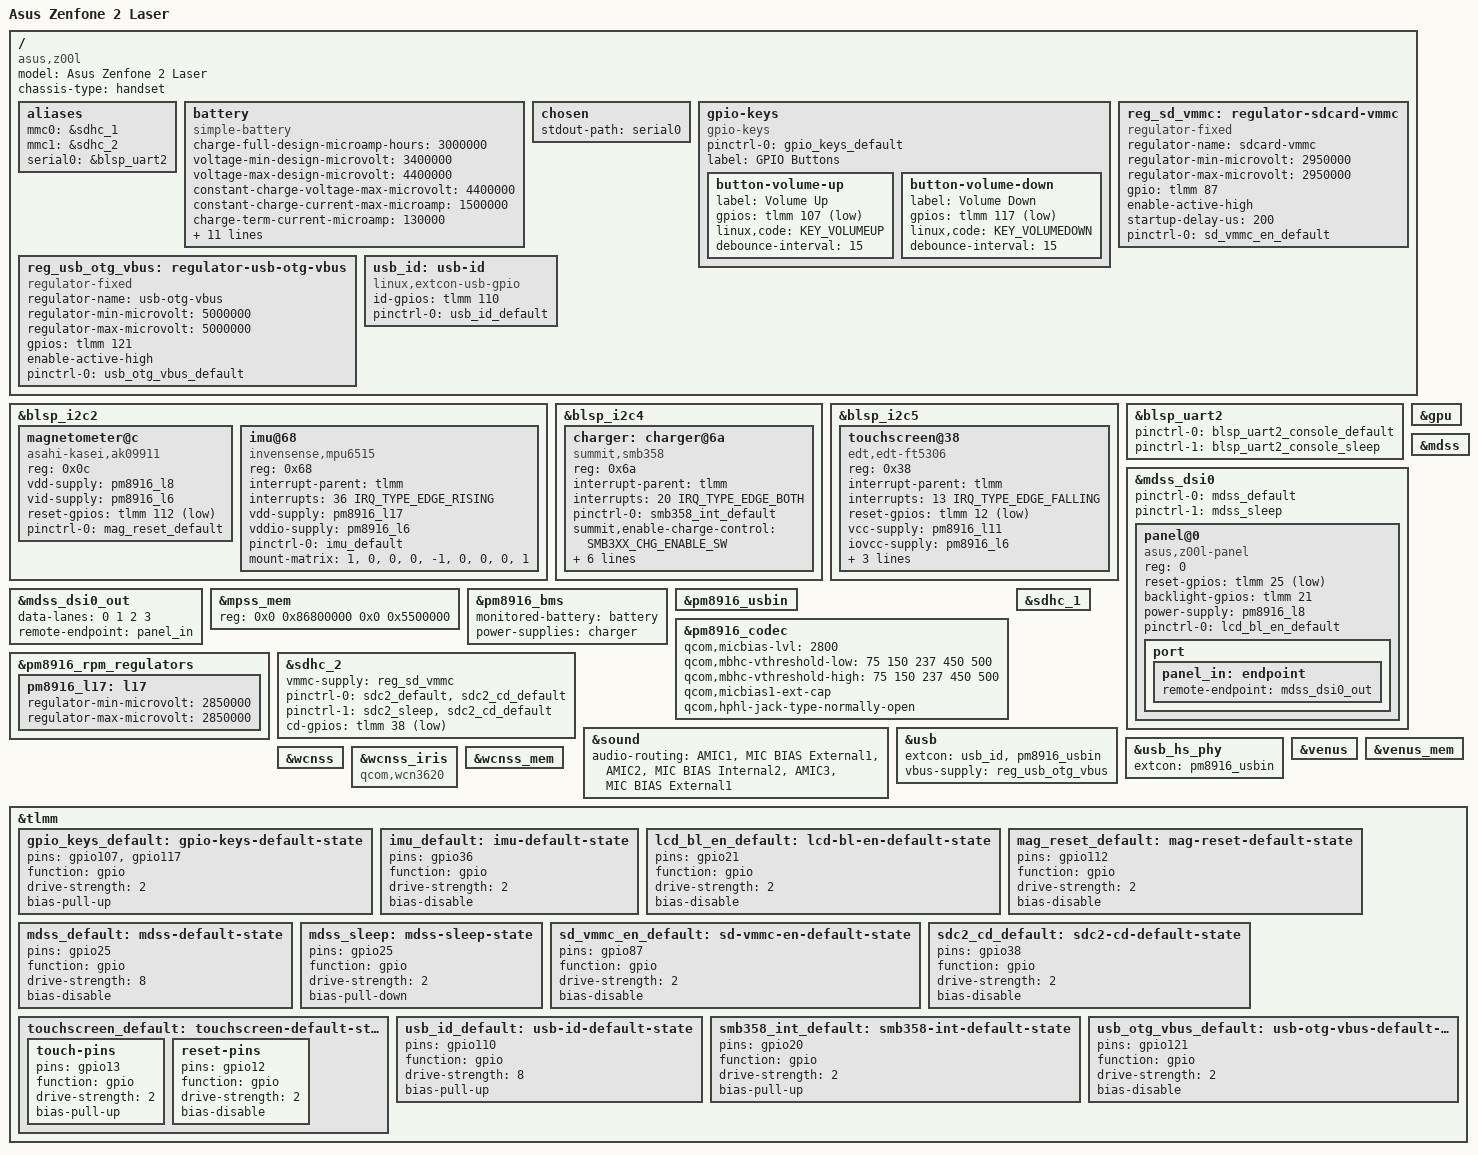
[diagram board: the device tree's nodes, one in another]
// SPDX-License-Identifier: GPL-2.0-only

/dts-v1/;

#include "msm8916-pm8916.dtsi"
#include "msm8916-modem-qdsp6.dtsi"

#include <dt-bindings/gpio/gpio.h>
#include <dt-bindings/input/input.h>
#include <dt-bindings/interrupt-controller/irq.h>
#include <dt-bindings/power/summit,smb347-charger.h>

/ {
	model = "Asus Zenfone 2 Laser";
	compatible = "asus,z00l", "qcom,msm8916";
	chassis-type = "handset";

	aliases {
		mmc0 = &sdhc_1; /* eMMC */
		mmc1 = &sdhc_2; /* SD card */
		serial0 = &blsp_uart2;
	};

	battery: battery {
		compatible = "simple-battery";

		charge-full-design-microamp-hours = <3000000>;
		voltage-min-design-microvolt = <3400000>;
		voltage-max-design-microvolt = <4400000>;
		constant-charge-voltage-max-microvolt = <4400000>;

		constant-charge-current-max-microamp = <1500000>;
		charge-term-current-microamp = <130000>;

		ocv-capacity-celsius = <25>;
		ocv-capacity-table-0 = <4372000 100>, <4306000 95>, <4247000 90>,
				       <4190000 85>,  <4134000 80>, <4081000 75>,
				       <4030000 70>,  <3984000 65>, <3930000 60>,
				       <3884000 55>,  <3850000 50>, <3826000 45>,
				       <3804000 40>,  <3786000 35>, <3770000 30>,
				       <3753000 25>,  <3734000 20>, <3712000 16>,
				       <3693000 13>,  <3686000 11>, <3684000 10>,
				       <3682000 9>,   <3680000 8>,  <3676000 7>,
				       <3668000 6>,   <3643000 5>,  <3600000 4>,
				       <3542000 3>,   <3462000 2>,  <3340000 1>,
				       <3000000 0>;
	};

	chosen {
		stdout-path = "serial0";
	};

	gpio-keys {
		compatible = "gpio-keys";

		pinctrl-names = "default";
		pinctrl-0 = <&gpio_keys_default>;

		label = "GPIO Buttons";

		button-volume-up {
			label = "Volume Up";
			gpios = <&tlmm 107 GPIO_ACTIVE_LOW>;
			linux,code = <KEY_VOLUMEUP>;
			debounce-interval = <15>;
		};

		button-volume-down {
			label = "Volume Down";
			gpios = <&tlmm 117 GPIO_ACTIVE_LOW>;
			linux,code = <KEY_VOLUMEDOWN>;
			debounce-interval = <15>;
		};
	};

	reg_sd_vmmc: regulator-sdcard-vmmc {
		compatible = "regulator-fixed";
		regulator-name = "sdcard-vmmc";
		regulator-min-microvolt = <2950000>;
		regulator-max-microvolt = <2950000>;

		gpio = <&tlmm 87 GPIO_ACTIVE_HIGH>;
		enable-active-high;

		startup-delay-us = <200>;

		pinctrl-names = "default";
		pinctrl-0 = <&sd_vmmc_en_default>;
	};

	reg_usb_otg_vbus: regulator-usb-otg-vbus {
		compatible = "regulator-fixed";
		regulator-name = "usb-otg-vbus";
		regulator-min-microvolt = <5000000>;
		regulator-max-microvolt = <5000000>;

		gpios = <&tlmm 121 GPIO_ACTIVE_HIGH>;
		enable-active-high;

		pinctrl-names = "default";
		pinctrl-0 = <&usb_otg_vbus_default>;
	};

	usb_id: usb-id {
		compatible = "linux,extcon-usb-gpio";
		id-gpios = <&tlmm 110 GPIO_ACTIVE_HIGH>;
		pinctrl-names = "default";
		pinctrl-0 = <&usb_id_default>;
	};
};

&blsp_i2c2 {
	status = "okay";

	magnetometer@c {
		compatible = "asahi-kasei,ak09911";
		reg = <0x0c>;

		vdd-supply = <&pm8916_l8>;
		vid-supply = <&pm8916_l6>;

		reset-gpios = <&tlmm 112 GPIO_ACTIVE_LOW>;

		pinctrl-names = "default";
		pinctrl-0 = <&mag_reset_default>;
	};

	imu@68 {
		compatible = "invensense,mpu6515";
		reg = <0x68>;

		interrupt-parent = <&tlmm>;
		interrupts = <36 IRQ_TYPE_EDGE_RISING>;

		vdd-supply = <&pm8916_l17>;
		vddio-supply = <&pm8916_l6>;

		pinctrl-names = "default";
		pinctrl-0 = <&imu_default>;

		mount-matrix = "1",  "0", "0",
			       "0", "-1", "0",
			       "0",  "0", "1";
	};
};

&blsp_i2c4 {
	status = "okay";

	charger: charger@6a {
		compatible = "summit,smb358";
		reg = <0x6a>;

		interrupt-parent = <&tlmm>;
		interrupts = <20 IRQ_TYPE_EDGE_BOTH>;

		pinctrl-names = "default";
		pinctrl-0 = <&smb358_int_default>;

		summit,enable-charge-control = <SMB3XX_CHG_ENABLE_SW>;
		summit,inok-polarity = <SMB3XX_SYSOK_INOK_ACTIVE_LOW>;
		summit,chip-temperature-threshold-celsius = <110>;
		summit,usb-current-limit-microamp = <1500000>;
		summit,enable-usb-charging;

		monitored-battery = <&battery>;
	};
};

&blsp_i2c5 {
	status = "okay";

	touchscreen@38 {
		compatible = "edt,edt-ft5306";
		reg = <0x38>;

		interrupt-parent = <&tlmm>;
		interrupts = <13 IRQ_TYPE_EDGE_FALLING>;

		reset-gpios = <&tlmm 12 GPIO_ACTIVE_LOW>;

		vcc-supply = <&pm8916_l11>;
		iovcc-supply = <&pm8916_l6>;

		touchscreen-size-x = <720>;
		touchscreen-size-y = <1280>;

		pinctrl-names = "default";
		pinctrl-0 = <&touchscreen_default>;
	};
};

&blsp_uart2 {
	status = "okay";
	pinctrl-0 = <&blsp_uart2_console_default>;
	pinctrl-1 = <&blsp_uart2_console_sleep>;
	pinctrl-names = "default", "sleep";
};

&gpu {
	status = "okay";
};

&mdss {
	status = "okay";
};

&mdss_dsi0 {
	pinctrl-names = "default", "sleep";
	pinctrl-0 = <&mdss_default>;
	pinctrl-1 = <&mdss_sleep>;

	panel@0 {
		compatible = "asus,z00l-panel";
		reg = <0>;

		reset-gpios = <&tlmm 25 GPIO_ACTIVE_LOW>;
		backlight-gpios = <&tlmm 21 GPIO_ACTIVE_HIGH>;
		power-supply = <&pm8916_l8>;

		pinctrl-names = "default";
		pinctrl-0 = <&lcd_bl_en_default>;

		port {
			panel_in: endpoint {
				remote-endpoint = <&mdss_dsi0_out>;
			};
		};
	};
};

&mdss_dsi0_out {
	data-lanes = <0 1 2 3>;
	remote-endpoint = <&panel_in>;
};

&mpss_mem {
	reg = <0x0 0x86800000 0x0 0x5500000>;
};

&pm8916_bms {
	status = "okay";
	monitored-battery = <&battery>;
	power-supplies = <&charger>;
};

&pm8916_usbin {
	status = "okay";
};

&pm8916_codec {
	qcom,micbias-lvl = <2800>;
	qcom,mbhc-vthreshold-low = <75 150 237 450 500>;
	qcom,mbhc-vthreshold-high = <75 150 237 450 500>;
	qcom,micbias1-ext-cap;
	qcom,hphl-jack-type-normally-open;
};

&pm8916_rpm_regulators {
	pm8916_l17: l17 {
		regulator-min-microvolt = <2850000>;
		regulator-max-microvolt = <2850000>;
	};
};

&sdhc_1 {
	status = "okay";
};

&sdhc_2 {
	status = "okay";
	vmmc-supply = <&reg_sd_vmmc>;

	pinctrl-names = "default", "sleep";
	pinctrl-0 = <&sdc2_default &sdc2_cd_default>;
	pinctrl-1 = <&sdc2_sleep &sdc2_cd_default>;
	cd-gpios = <&tlmm 38 GPIO_ACTIVE_LOW>;
};

&sound {
	audio-routing =
		"AMIC1", "MIC BIAS External1",
		"AMIC2", "MIC BIAS Internal2",
		"AMIC3", "MIC BIAS External1";
};

&usb {
	status = "okay";
	extcon = <&usb_id>, <&pm8916_usbin>;
	vbus-supply = <&reg_usb_otg_vbus>;
};

&usb_hs_phy {
	extcon = <&pm8916_usbin>;
};

&venus {
	status = "okay";
};

&venus_mem {
	status = "okay";
};

&wcnss {
	status = "okay";
};

&wcnss_iris {
	compatible = "qcom,wcn3620";
};

&wcnss_mem {
	status = "okay";
};

&tlmm {
	gpio_keys_default: gpio-keys-default-state {
		pins = "gpio107", "gpio117";
		function = "gpio";

		drive-strength = <2>;
		bias-pull-up;
	};

	imu_default: imu-default-state {
		pins = "gpio36";
		function = "gpio";

		drive-strength = <2>;
		bias-disable;
	};

	lcd_bl_en_default: lcd-bl-en-default-state {
		pins = "gpio21";
		function = "gpio";

		drive-strength = <2>;
		bias-disable;
	};

	mag_reset_default: mag-reset-default-state {
		pins = "gpio112";
		function = "gpio";

		drive-strength = <2>;
		bias-disable;
	};

	mdss_default: mdss-default-state {
		pins = "gpio25";
		function = "gpio";

		drive-strength = <8>;
		bias-disable;
	};

	mdss_sleep: mdss-sleep-state {
		pins = "gpio25";
		function = "gpio";

		drive-strength = <2>;
		bias-pull-down;
	};

	sd_vmmc_en_default: sd-vmmc-en-default-state {
		pins = "gpio87";
		function = "gpio";

		drive-strength = <2>;
		bias-disable;
	};

	sdc2_cd_default: sdc2-cd-default-state {
		pins = "gpio38";
		function = "gpio";
		drive-strength = <2>;
		bias-disable;
	};

	touchscreen_default: touchscreen-default-state {
		touch-pins {
			pins = "gpio13";
			function = "gpio";

			drive-strength = <2>;
			bias-pull-up;
		};

		reset-pins {
			pins = "gpio12";
			function = "gpio";

			drive-strength = <2>;
			bias-disable;
		};
	};

	usb_id_default: usb-id-default-state {
		pins = "gpio110";
		function = "gpio";

		drive-strength = <8>;
		bias-pull-up;
	};

	smb358_int_default: smb358-int-default-state {
		pins = "gpio20";
		function = "gpio";
		drive-strength = <2>;
		bias-pull-up;
	};

	usb_otg_vbus_default: usb-otg-vbus-default-state {
		pins = "gpio121";
		function = "gpio";
		drive-strength = <2>;
		bias-disable;
	};
};
